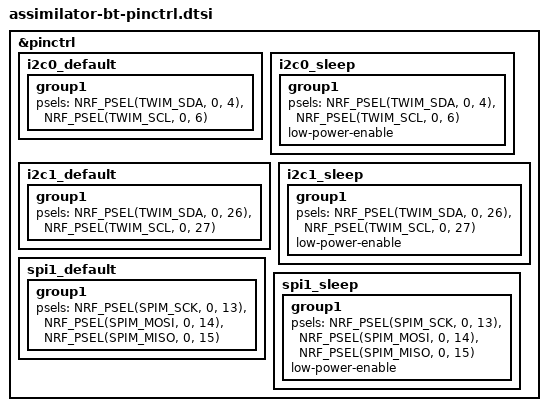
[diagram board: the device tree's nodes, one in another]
/*
 * Copyright (c) 2022 The ZMK Contributors
 * SPDX-License-Identifier: MIT
 */

&pinctrl {

    i2c0_default: i2c0_default {
        group1 {
            psels = <NRF_PSEL(TWIM_SDA, 0, 4)>,
                <NRF_PSEL(TWIM_SCL, 0, 6)>;
        };
    };

    i2c0_sleep: i2c0_sleep {
        group1 {
            psels = <NRF_PSEL(TWIM_SDA, 0, 4)>,
                <NRF_PSEL(TWIM_SCL, 0, 6)>;
            low-power-enable;
        };
    };

    i2c1_default: i2c1_default {
        group1 {
            psels = <NRF_PSEL(TWIM_SDA, 0, 26)>,
                <NRF_PSEL(TWIM_SCL, 0, 27)>;
        };
    };

    i2c1_sleep: i2c1_sleep {
        group1 {
            psels = <NRF_PSEL(TWIM_SDA, 0, 26)>,
                <NRF_PSEL(TWIM_SCL, 0, 27)>;
            low-power-enable;
        };
    };

    // Dummy SPI1 configuration to satisfy upstream shield requirements
    // Not actually used since Cirque uses I2C
    spi1_default: spi1_default {
        group1 {
            psels = <NRF_PSEL(SPIM_SCK, 0, 13)>,
                <NRF_PSEL(SPIM_MOSI, 0, 14)>,
                <NRF_PSEL(SPIM_MISO, 0, 15)>;
        };
    };

    spi1_sleep: spi1_sleep {
        group1 {
            psels = <NRF_PSEL(SPIM_SCK, 0, 13)>,
                <NRF_PSEL(SPIM_MOSI, 0, 14)>,
                <NRF_PSEL(SPIM_MISO, 0, 15)>;
            low-power-enable;
        };
    };
};
